# ESP32-H21 register map
Vendor: ESPRESSIF SYSTEMS (SHANGHAI) CO., LTD.; Series: ESP32 H-Series; File version: 1
CPU: RV32IMAC r0p0, little endian, no MPU, no FPU, 0 interrupt priority bits
Address unit: 32 bits
Registers are 32-bit, read-write, reset 0x0 unless marked. A register's access mark holds for its fields unless they carry their own. Offsets are from the block's base; [hi:lo] are bit positions; {n}, {i} and the like mark numbered series.

## RMT — Remote Control
Base 0x60007000
{0x0+4i} CH{i}DATA (i=0..3) — The read and write data register for CHANNEL{i} by apb fifo access.
  [31:0] DATA — Read and write data for channel %s via APB FIFO.
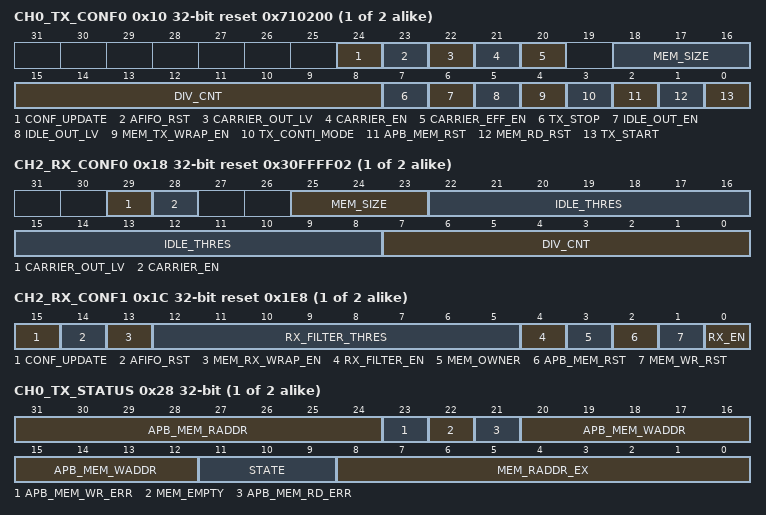
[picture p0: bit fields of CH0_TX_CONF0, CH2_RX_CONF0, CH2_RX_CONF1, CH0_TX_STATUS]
{0x10+4i} CH{i}_TX_CONF0 (i=0..1) access per field reset 0x710200 — Channel {i} configure register 0
  [24] CONF_UPDATE wo — synchronization bit for CHANNEL%s
  [23] AFIFO_RST wo — Reserved
  [22] CARRIER_OUT_LV rw — This bit is used to configure the position of carrier wave for CHANNEL%s. 1'h0: add carrier wave on low level. 1'h1: add carrier wave on high level.
  [21] CARRIER_EN rw — This is the carrier modulation enable-control bit for CHANNEL%s. 1: Add carrier modulation in the output signal. 0: No carrier modulation in sig_out.
  [20] CARRIER_EFF_EN rw — 1: Add carrier modulation on the output signal only at the send data state for CHANNEL%s. 0: Add carrier modulation on the output signal at all state for CHANNEL%s. Only valid when RMT_CARRIER_EN_CH%s is 1.
  [18:16] MEM_SIZE rw — This register is used to configure the maximum size of memory allocated to CHANNEL%s.
  [15:8] DIV_CNT rw — This register is used to configure the divider for clock of CHANNEL%s.
  [7] TX_STOP rw — Set this bit to stop the transmitter of CHANNEL%s sending data out.
  [6] IDLE_OUT_EN rw — This is the output enable-control bit for CHANNEL%s in IDLE state.
  [5] IDLE_OUT_LV rw — This bit configures the level of output signal in CHANNEL%s when the latter is in IDLE state.
  [4] MEM_TX_WRAP_EN rw — This is the channel %s enable bit for wraparound mode: it will resume sending at the start when the data to be sent is more than its memory size.
  [3] TX_CONTI_MODE rw — Set this bit to restart transmission from the first data to the last data in CHANNEL%s.
  [2] APB_MEM_RST wo — Set this bit to reset W/R ram address for CHANNEL%s by accessing apb fifo.
  [1] MEM_RD_RST wo — Set this bit to reset read ram address for CHANNEL%s by accessing transmitter.
  [0] TX_START wo — Set this bit to start sending data on CHANNEL%s.
{0x8+8i} CH{i}_RX_CONF0 (i=2..3) reset 0x30FFFF02 — Channel {i} configure register 0
  [29] CARRIER_OUT_LV — This bit is used to configure the position of carrier wave for CHANNEL%s. 1'h0: add carrier wave on low level. 1'h1: add carrier wave on high level.
  [28] CARRIER_EN — This is the carrier modulation enable-control bit for CHANNEL%s. 1: Add carrier modulation in the output signal. 0: No carrier modulation in sig_out.
  [25:23] MEM_SIZE — This register is used to configure the maximum size of memory allocated to CHANNEL%s.
  [22:8] IDLE_THRES — When no edge is detected on the input signal and continuous clock cycles is longer than this register value, received process is finished.
  [7:0] DIV_CNT — This register is used to configure the divider for clock of CHANNEL%s.
{0xC+8i} CH{i}_RX_CONF1 (i=2..3) access per field reset 0x1E8 — Channel {i} configure register 1
  [15] CONF_UPDATE wo — synchronization bit for CHANNEL%s
  [14] AFIFO_RST wo — Reserved
  [13] MEM_RX_WRAP_EN rw — This is the channel %s enable bit for wraparound mode: it will resume receiving at the start when the data to be received is more than its memory size.
  [12:5] RX_FILTER_THRES rw — Ignores the input pulse when its width is smaller than this register value in APB clock periods (in receive mode).
  [4] RX_FILTER_EN rw — This is the receive filter's enable bit for CHANNEL%s.
  [3] MEM_OWNER rw — This register marks the ownership of CHANNEL%s's ram block. 1'h1: Receiver is using the ram. 1'h0: APB bus is using the ram.
  [2] APB_MEM_RST wo — Set this bit to reset W/R ram address for CHANNEL%s by accessing apb fifo.
  [1] MEM_WR_RST wo — Set this bit to reset write ram address for CHANNEL%s by accessing receiver.
  [0] RX_EN rw — Set this bit to enable receiver to receive data on CHANNEL%s.
{0x28+4i} CH{i}_TX_STATUS (i=0..1) ro — Channel {i} status register
  [31:24] APB_MEM_RADDR — This register records the memory address offset when reading RAM over APB bus.
  [23] APB_MEM_WR_ERR — This status bit will be set if the offset address out of memory size when writes via APB bus.
  [22] MEM_EMPTY — This status bit will be set when the data to be set is more than memory size and the wraparound mode is disabled.
  [21] APB_MEM_RD_ERR — This status bit will be set if the offset address out of memory size when reading via APB bus.
  [20:12] APB_MEM_WADDR — This register records the memory address offset when writes RAM over APB bus.
  [11:9] STATE — This register records the FSM status of CHANNEL%s.
  [8:0] MEM_RADDR_EX — This register records the memory address offset when transmitter of CHANNEL%s is using the RAM.
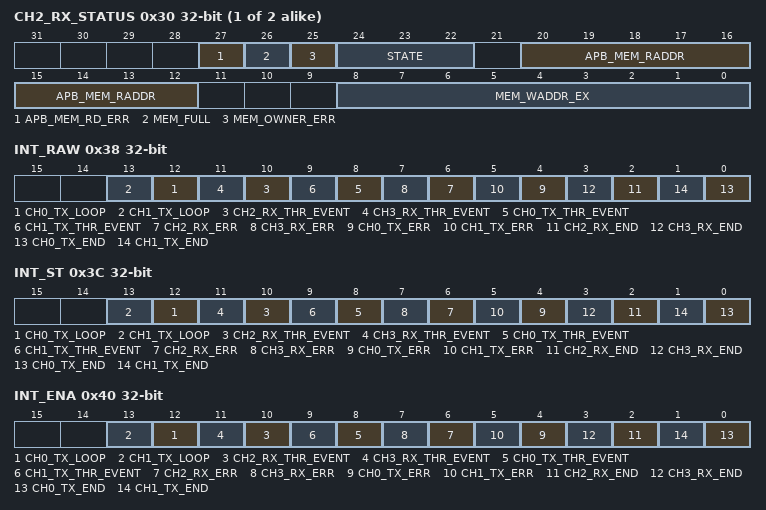
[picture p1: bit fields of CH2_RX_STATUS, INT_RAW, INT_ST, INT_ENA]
{0x28+4i} CH{i}_RX_STATUS (i=2..3) ro — Channel {i} status register
  [27] APB_MEM_RD_ERR — This status bit will be set if the offset address out of memory size when reads via APB bus.
  [26] MEM_FULL — This status bit will be set if the receiver receives more data than the memory size.
  [25] MEM_OWNER_ERR — This status bit will be set when the ownership of memory block is wrong.
  [24:22] STATE — This register records the FSM status of CHANNEL%s.
  [20:12] APB_MEM_RADDR — This register records the memory address offset when reads RAM over APB bus.
  [8:0] MEM_WADDR_EX — This register records the memory address offset when receiver of CHANNEL%s is using the RAM.
0x38 INT_RAW — Raw interrupt status
  [n+12] CH{n}_TX_LOOP (n=0..1) — The interrupt raw bit for CHANNEL{n}. Triggered when the loop count reaches the configured threshold value.
  [n+8] CH{n}_RX_THR_EVENT (n=2..3) — The interrupt raw bit for CHANNEL{n}. Triggered when receiver receive more data than configured value.
  [n+8] CH{n}_TX_THR_EVENT (n=0..1) — The interrupt raw bit for CHANNEL{n}. Triggered when transmitter sent more data than configured value.
  [n+4] CH{n}_RX_ERR (n=2..3) — todo
  [n+4] CH{n}_TX_ERR (n=0..1) — todo
  [n] CH{n}_RX_END (n=2..3) — The interrupt raw bit for CHANNEL{n}. Triggered when reception done.
  [n] CH{n}_TX_END (n=0..1) — The interrupt raw bit for CHANNEL{n}. Triggered when transmission done.
0x3C INT_ST ro — Masked interrupt status
  [n+12] CH{n}_TX_LOOP (n=0..1) — The masked interrupt status bit for CH{n}_TX_LOOP_INT.
  [n+8] CH{n}_RX_THR_EVENT (n=2..3) — The masked interrupt status bit for CH{n}_RX_THR_EVENT_INT.
  [n+8] CH{n}_TX_THR_EVENT (n=0..1) — The masked interrupt status bit for CH{n}_TX_THR_EVENT_INT.
  [n+4] CH{n}_RX_ERR (n=2..3) — todo
  [n+4] CH{n}_TX_ERR (n=0..1) — todo
  [n] CH{n}_RX_END (n=2..3) — The masked interrupt status bit for CH{n}_RX_END_INT.
  [n] CH{n}_TX_END (n=0..1) — The masked interrupt status bit for CH{n}_TX_END_INT.
0x40 INT_ENA — Interrupt enable bits
  [n+12] CH{n}_TX_LOOP (n=0..1) — The interrupt enable bit for CH{n}_TX_LOOP_INT.
  [n+8] CH{n}_RX_THR_EVENT (n=2..3) — The interrupt enable bit for CH{n}_RX_THR_EVENT_INT.
  [n+8] CH{n}_TX_THR_EVENT (n=0..1) — The interrupt enable bit for CH{n}_TX_THR_EVENT_INT.
  [n+4] CH{n}_RX_ERR (n=2..3) — todo
  [n+4] CH{n}_TX_ERR (n=0..1) — todo
  [n] CH{n}_RX_END (n=2..3) — The interrupt enable bit for CH{n}_RX_END_INT.
  [n] CH{n}_TX_END (n=0..1) — The interrupt enable bit for CH{n}_TX_END_INT.
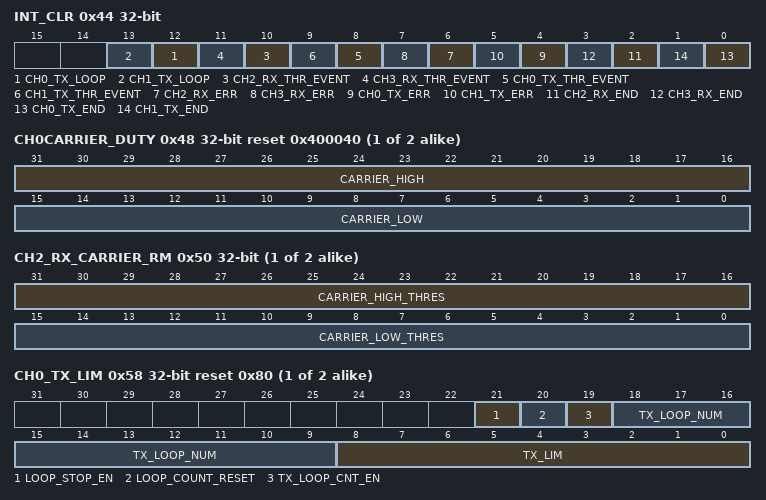
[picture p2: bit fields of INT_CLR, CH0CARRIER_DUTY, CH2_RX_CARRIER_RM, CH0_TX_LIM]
0x44 INT_CLR wo — Interrupt clear bits
  [n+12] CH{n}_TX_LOOP (n=0..1) — Set this bit to clear theCH{n}_TX_LOOP_INT interrupt.
  [n+8] CH{n}_RX_THR_EVENT (n=2..3) — Set this bit to clear theCH{n}_RX_THR_EVENT_INT interrupt.
  [n+8] CH{n}_TX_THR_EVENT (n=0..1) — Set this bit to clear theCH{n}_TX_THR_EVENT_INT interrupt.
  [n+4] CH{n}_RX_ERR (n=2..3) — todo
  [n+4] CH{n}_TX_ERR (n=0..1) — todo
  [n] CH{n}_RX_END (n=2..3) — Set this bit to clear theCH{n}_RX_END_INT interrupt.
  [n] CH{n}_TX_END (n=0..1) — Set this bit to clear theCH{n}_TX_END_INT interrupt.
{0x48+4i} CH{i}CARRIER_DUTY (i=0..1) reset 0x400040 — Channel {i} duty cycle configuration register
  [31:16] CARRIER_HIGH — This register is used to configure carrier wave 's high level clock period for CHANNEL%s.
  [15:0] CARRIER_LOW — This register is used to configure carrier wave 's low level clock period for CHANNEL%s.
{0x48+4i} CH{i}_RX_CARRIER_RM (i=2..3) — Channel {i} carrier remove register
  [31:16] CARRIER_HIGH_THRES — The high level period in a carrier modulation mode is (REG_RMT_REG_CARRIER_HIGH_THRES_CH%s + 1) for channel %s.
  [15:0] CARRIER_LOW_THRES — The low level period in a carrier modulation mode is (REG_RMT_REG_CARRIER_LOW_THRES_CH%s + 1) for channel %s.
{0x58+4i} CH{i}_TX_LIM (i=0..1) access per field reset 0x80 — Channel {i} Tx event configuration register
  [21] LOOP_STOP_EN rw — This bit is used to enable the loop send stop function after the loop counter counts to loop number for CHANNEL%s.
  [20] LOOP_COUNT_RESET wo — This register is used to reset the loop count when tx_conti_mode is valid.
  [19] TX_LOOP_CNT_EN rw — This register is the enabled bit for loop count.
  [18:9] TX_LOOP_NUM rw — This register is used to configure the maximum loop count when tx_conti_mode is valid.
  [8:0] TX_LIM rw — This register is used to configure the maximum entries that CHANNEL%s can send out.
{0x58+4i} CH{i}_RX_LIM (i=2..3) reset 0x80 — Channel {i} Rx event configuration register
  [8:0] RX_LIM — This register is used to configure the maximum entries that CHANNEL%s can receive.
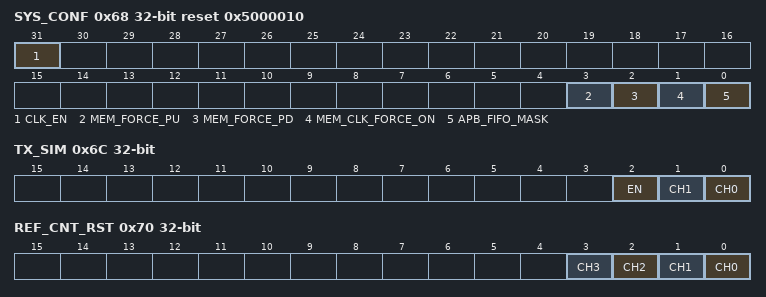
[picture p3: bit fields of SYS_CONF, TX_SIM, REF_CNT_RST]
0x68 SYS_CONF reset 0x5000010 — RMT apb configuration register
  [31] CLK_EN — RMT register clock gate enable signal. 1: Power up the drive clock of registers. 0: Power down the drive clock of registers
  [3] MEM_FORCE_PU — 1: Disable RMT memory light sleep power down function. 0: Power down RMT memory when RMT is in light sleep mode.
  [2] MEM_FORCE_PD — Set this bit to power down RMT memory.
  [1] MEM_CLK_FORCE_ON — Set this bit to enable the clock for RMT memory.
  [0] APB_FIFO_MASK — 1'h1: access memory directly. 1'h0: access memory by FIFO.
0x6C TX_SIM — RMT TX synchronous register
  [2] EN — This register is used to enable multiple of channels to start sending data synchronously.
  [1] CH1 — Set this bit to enable CHANNEL1 to start sending data synchronously with other enabled channels.
  [0] CH0 — Set this bit to enable CHANNEL0 to start sending data synchronously with other enabled channels.
0x70 REF_CNT_RST wo — RMT clock divider reset register
  [n] CH{n} (n=0..3) — This register is used to reset the clock divider of CHANNEL{n}.
0xCC DATE — RMT version register
